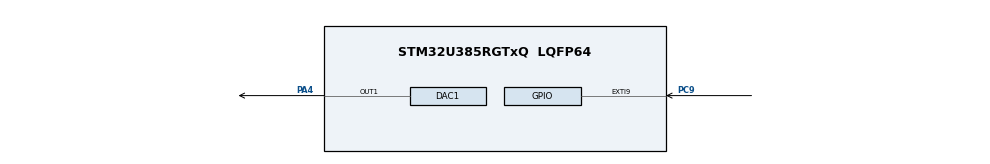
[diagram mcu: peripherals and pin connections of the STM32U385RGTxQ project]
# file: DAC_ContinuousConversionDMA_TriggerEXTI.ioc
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CORTEX_M33_NS.userName=CORTEX_M33
DAC1.DAC_Channel-DAC_OUT1=DAC_CHANNEL_1
DAC1.DAC_Trigger-DAC_OUT1=DAC_TRIGGER_EXT_IT9
GPDMA1.CIRCULARMODE_GPDMACH1=ENABLE
GPDMA1.DESTDATAWIDTH_GPDMACH1=DMA_DEST_DATAWIDTH_WORD
GPDMA1.DESTINC_GPDMACH1=DMA_DINC_FIXED
GPDMA1.DIRECTION_GPDMACH1=DMA_MEMORY_TO_PERIPH
GPDMA1.IPHANDLE_GPDMACH1-SIMPLEREQUEST_GPDMACH1=__NULL
GPDMA1.LINKALLOCATEDPORT_CIRCULAR_GPDMACH1=DMA_LINK_ALLOCATED_PORT1
GPDMA1.RECAP_GPDMACH1=GPDMA1_REQUEST_DAC1_CH1
GPDMA1.REQUEST_GPDMACH1=GPDMA1_REQUEST_DAC1_CH1
GPDMA1.SRCINC_GPDMACH1=DMA_SINC_INCREMENTED
GPDMA1.TRANSFERALLOCATEDPORTDEST_GPDMACH1=DMA_DEST_ALLOCATED_PORT0
GPDMA1.TRANSFERALLOCATEDPORTSRC_GPDMACH1=DMA_SRC_ALLOCATED_PORT1
Mcu.Family=STM32U3
Mcu.Name=STM32U385RGTxQ
Mcu.Package=LQFP64
NVIC.GPDMA1_Channel1_IRQn=true\:0\:0\:false\:false\:true\:false\:true\:true
NVIC.PriorityGroup=NVIC_PRIORITYGROUP_4
PA4.Signal=COMP_DAC11_group
PC9.Signal=GPXTI9
ProjectManager.HeapSize=0x200
ProjectManager.StackSize=0x400
ProjectManager.TargetToolchain=EWARM V8
RCC.ADCFreq_Value=96000000
RCC.AHBFreq_Value=96000000
RCC.APB1Freq_Value=96000000
RCC.APB1TimFreq_Value=96000000
RCC.APB2Freq_Value=96000000
RCC.APB2TimFreq_Value=96000000
RCC.APB3Freq_Value=96000000
RCC.CortexFreq_Value=12000000
RCC.HCLKFreq_Value=96000000
RCC.HSE_VALUE=16000000
RCC.HSI48_VALUE=48000000
RCC.HSI_VALUE=16000000
RCC.LSE_VALUE=32768
RCC.LSIDIV_VALUE=32000
RCC.MSISDIV=RCC_MSI_DIV1
RCC.SYSCLKFreq_VALUE=96000000
RCC.USBFreq_Value=96000000
SH.COMP_DAC11_group.0=DAC1_OUT1,DAC_OUT1
VP_GPDMA1_VS_GPDMACH1.Mode=SIMPLEREQUEST_GPDMACH1
VP_ICACHE_VS_ICACHE.Mode=DirectMappedCache
VP_PWR_VS_DBSignals.Mode=DisableDeadBatterySignals
VP_PWR_VS_LPOM.Mode=PowerOptimisation
VP_PWR_VS_SECSignals.Mode=Security/Privilege
board=custom

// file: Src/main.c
/* USER CODE BEGIN Header */
/**
  ******************************************************************************
  * @file    Examples/DAC/DAC_ContinuousConversionDMA_TriggerEXTI/Src/main.c
  * @author  MCD Application Team
  * @brief   This example provides a short description of how to use the DAC
  *          peripheral to generate several signals.
  ******************************************************************************
  * @attention
  *
  * Copyright (c) 2024 STMicroelectronics.
  * All rights reserved.
  *
  * This software is licensed under terms that can be found in the LICENSE file
  * in the root directory of this software component.
  * If no LICENSE file comes with this software, it is provided AS-IS.
  *
  ******************************************************************************
  */
/* USER CODE END Header */
#include "main.h"

DAC_HandleTypeDef hdac1;
DMA_NodeTypeDef Node_GPDMA1_Channel1;
DMA_QListTypeDef List_GPDMA1_Channel1;
DMA_HandleTypeDef handle_GPDMA1_Channel1;

/* USER CODE BEGIN PV */
const uint8_t aEscalator8bit[6] = {0x0, 0x33, 0x66, 0x99, 0xCC, 0xFF};
/* USER CODE END PV */

void SystemClock_Config(void);
static void MX_GPIO_Init(void);
static void MX_GPDMA1_Init(void);
static void MX_DAC1_Init(void);
static void MX_ICACHE_Init(void);
/* USER CODE BEGIN PFP */
static void DAC_Ch1_EscalatorConfig(void);
/* USER CODE END PFP */

int main(void)
{

  /* MCU Configuration--------------------------------------------------------*/

  /* Reset of all peripherals, Initializes the Flash interface and the Systick. */
  HAL_Init();

  /* Configure the system clock */
  SystemClock_Config();

  /* Initialize all configured peripherals */
  MX_GPIO_Init();
  MX_GPDMA1_Init();
  MX_DAC1_Init();
  MX_ICACHE_Init();
  /* USER CODE BEGIN 2 */
  /* Configure LD2 */
  BSP_LED_Init(LD2);

  /* Configure User push-button in Interrupt mode */
  BSP_PB_Init(BUTTON_USER, BUTTON_MODE_EXTI);

  /* Escalator Wave generator */
  DAC_Ch1_EscalatorConfig();

  /* USER CODE END 2 */

  /* Infinite loop */
  while (1)
  {

  }
}

void SystemClock_Config(void)
{
  RCC_OscInitTypeDef RCC_OscInitStruct = {0};
  RCC_ClkInitTypeDef RCC_ClkInitStruct = {0};

  /** Enable Epod Booster
  */
  if (HAL_RCCEx_EpodBoosterClkConfig(RCC_EPODBOOSTER_SOURCE_MSIS, RCC_EPODBOOSTER_DIV1) != HAL_OK)
  {
    Error_Handler();
  }

  if (HAL_PWREx_EnableEpodBooster() != HAL_OK)
  {
    Error_Handler();
  }

  /** Configure the main internal regulator output voltage
  */
  if (HAL_PWREx_ControlVoltageScaling(PWR_REGULATOR_VOLTAGE_SCALE1) != HAL_OK)
  {
    Error_Handler();
  }

  /** Set Flash latency before increasing MSIS
  */
  __HAL_FLASH_SET_LATENCY(FLASH_LATENCY_2);

  /** Initializes the CPU, AHB and APB buses clocks
  */
  RCC_OscInitStruct.OscillatorType = RCC_OSCILLATORTYPE_LSI|RCC_OSCILLATORTYPE_MSIS;
  RCC_OscInitStruct.LSIState = RCC_LSI_ON;
  RCC_OscInitStruct.LSIDiv = RCC_LSI_DIV1;
  RCC_OscInitStruct.MSISState = RCC_MSI_ON;
  RCC_OscInitStruct.MSISSource = RCC_MSI_RC0;
  RCC_OscInitStruct.MSISDiv = RCC_MSI_DIV1;
  if (HAL_RCC_OscConfig(&RCC_OscInitStruct) != HAL_OK)
  {
    Error_Handler();
  }

  /** Initializes the CPU, AHB and APB buses clocks
  */
  RCC_ClkInitStruct.ClockType = RCC_CLOCKTYPE_HCLK|RCC_CLOCKTYPE_SYSCLK
                              |RCC_CLOCKTYPE_PCLK1|RCC_CLOCKTYPE_PCLK2
                              |RCC_CLOCKTYPE_PCLK3;
  RCC_ClkInitStruct.SYSCLKSource = RCC_SYSCLKSOURCE_MSIS;
  RCC_ClkInitStruct.AHBCLKDivider = RCC_SYSCLK_DIV1;
  RCC_ClkInitStruct.APB1CLKDivider = RCC_HCLK_DIV1;
  RCC_ClkInitStruct.APB2CLKDivider = RCC_HCLK_DIV1;
  RCC_ClkInitStruct.APB3CLKDivider = RCC_HCLK_DIV1;

  if (HAL_RCC_ClockConfig(&RCC_ClkInitStruct, FLASH_LATENCY_2) != HAL_OK)
  {
    Error_Handler();
  }
}

static void MX_DAC1_Init(void)
{

  DAC_ChannelConfTypeDef sConfig = {0};
  DAC_AutonomousModeConfTypeDef sAutonomousMode = {0};

  /** DAC Initialization
  */
  hdac1.Instance = DAC1;
  if (HAL_DAC_Init(&hdac1) != HAL_OK)
  {
    Error_Handler();
  }

  /** DAC channel OUT1 config
  */
  sConfig.DAC_HighFrequency = DAC_HIGH_FREQUENCY_INTERFACE_MODE_DISABLE;
  sConfig.DAC_DMADoubleDataMode = DISABLE;
  sConfig.DAC_SignedFormat = DISABLE;
  sConfig.DAC_SampleAndHold = DAC_SAMPLEANDHOLD_DISABLE;
  sConfig.DAC_Trigger = DAC_TRIGGER_EXT_IT9;
  sConfig.DAC_OutputBuffer = DAC_OUTPUTBUFFER_DISABLE;
  sConfig.DAC_ConnectOnChipPeripheral = DAC_CHIPCONNECT_EXTERNAL;
  sConfig.DAC_UserTrimming = DAC_TRIMMING_FACTORY;
  if (HAL_DAC_ConfigChannel(&hdac1, &sConfig, DAC_CHANNEL_1) != HAL_OK)
  {
    Error_Handler();
  }

  /** Configure Autonomous Mode
  */
  sAutonomousMode.AutonomousModeState = DAC_AUTONOMOUS_MODE_DISABLE;
  if (HAL_DACEx_SetConfigAutonomousMode(&hdac1, &sAutonomousMode) != HAL_OK)
  {
    Error_Handler();
  }

}

static void MX_GPDMA1_Init(void)
{

  /* Peripheral clock enable */
  __HAL_RCC_GPDMA1_CLK_ENABLE();

  /* GPDMA1 interrupt Init */
    HAL_NVIC_SetPriority(GPDMA1_Channel1_IRQn, 0, 0);
    HAL_NVIC_EnableIRQ(GPDMA1_Channel1_IRQn);

}

static void MX_ICACHE_Init(void)
{

  /** Enable instruction cache in 1-way (direct mapped cache)
  */
  if (HAL_ICACHE_ConfigAssociativityMode(ICACHE_1WAY) != HAL_OK)
  {
    Error_Handler();
  }
  if (HAL_ICACHE_Enable() != HAL_OK)
  {
    Error_Handler();
  }

}

static void MX_GPIO_Init(void)
{
  GPIO_InitTypeDef GPIO_InitStruct = {0};

  /* GPIO Ports Clock Enable */
  __HAL_RCC_GPIOA_CLK_ENABLE();
  __HAL_RCC_GPIOC_CLK_ENABLE();

  /*Configure GPIO pin : PC9 */
  GPIO_InitStruct.Pin = GPIO_PIN_9;
  GPIO_InitStruct.Mode = GPIO_MODE_IT_RISING;
  GPIO_InitStruct.Pull = GPIO_NOPULL;
  HAL_GPIO_Init(GPIOC, &GPIO_InitStruct);

}

/* USER CODE BEGIN 4 */
/**
  * @brief  DAC Channel1 EscalatorConfig
  * @param  None
  * @retval None
  */
static void DAC_Ch1_EscalatorConfig(void)
{
  /* Initialize the DAC peripheral */
  if (HAL_DAC_Init(&hdac1) != HAL_OK)
  {
    /* DAC initialization Error */
    Error_Handler();
  }

  /* Enable DAC selected channel and associated DMA */
  if (HAL_DAC_Start_DMA(&hdac1, DAC_CHANNEL_1, (uint32_t *)aEscalator8bit, 6, DAC_ALIGN_8B_R) != HAL_OK)
  {
    /* Start DMA Error */
    Error_Handler();
  }
}

/* USER CODE END 4 */

void Error_Handler(void)
{
  /* USER CODE BEGIN Error_Handler_Debug */
  /* Error if LD2 is slowly blinking (1 sec. period) */
  while(1)
  {
    BSP_LED_Toggle(LD2);
    HAL_Delay(1000);
  }
  /* USER CODE END Error_Handler_Debug */
}
